# PIC16F1947 register map
Vendor: Microchip
Registers are 8-bit, read-write, reset 0x0 unless marked. A register's access mark holds for its fields unless they carry their own. Addresses are absolute, and some are shared; only a register's first bit layout is shown; [hi:lo] are bit positions; {n}, {i} and the like mark numbered series; 'fields as' and 'values as' point back to an identical list.

## SFR
0x00 INDF0 reset not defined — (power-on value xxxxxxxx)
0x01 INDF1 reset not defined — (power-on value xxxxxxxx)
0x02 PCL
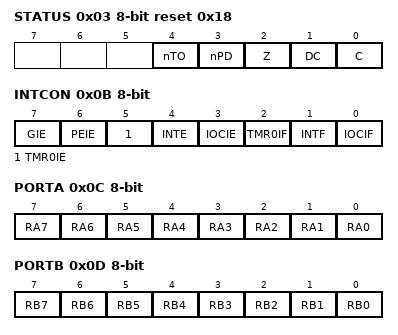
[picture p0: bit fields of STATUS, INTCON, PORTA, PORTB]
0x03 STATUS reset 0x18
  [4] nTO ro, [3] nPD ro, [2] Z, [1] DC, [0] C
0x04 FSR0L
0x05 FSR0H
0x06 FSR1L
0x07 FSR1H
0x08 BSR
  [4:0] BSR
0x09 WREG
  [7:0] WREG0
0x0A PCLATH
  [6:0] PCLATH
0x0B INTCON
  [7] GIE, [6] PEIE, [5] TMR0IE, [4] INTE, [3] IOCIE, [2] TMR0IF, [1] INTF, [0] IOCIF ro
0x0C PORTA reset not defined — (power-on value xxxxxxxx)
  [n] RA{n} (n=0..7)
0x0D PORTB reset not defined — (power-on value xxxxxxxx)
  [n] RB{n} (n=0..7)
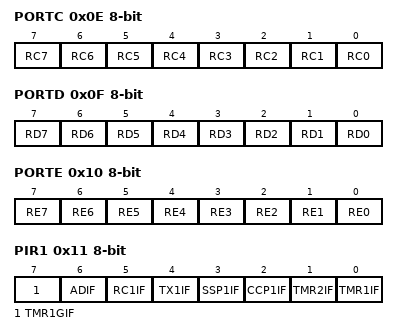
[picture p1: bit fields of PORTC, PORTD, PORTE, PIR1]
0x0E PORTC reset not defined — (power-on value xxxxxxxx)
  [n] RC{n} (n=0..7)
0x0F PORTD reset not defined — (power-on value xxxxxxxx)
  [n] RD{n} (n=0..7)
0x10 PORTE reset not defined — (power-on value xxxxxxxx)
  [n] RE{n} (n=0..7)
0x11 PIR1
  [7] TMR1GIF — Timer1 Gate Interrupt Flag bit
  [6] ADIF — A/D Converter Interrupt Flag bit
  [5] RC1IF ro — EUSART Receive Interrupt Flag bit
  [4] TX1IF ro — EUSART Transmit Interrupt Flag bit
  [3] SSP1IF — Master Synchronous Serial Port (MSSP) Interrupt Flag bit
  [2] CCP1IF — CCP1 Interrupt Flag bit
  [1] TMR2IF — TMR2 to PR2 Match Interrupt Flag bit
  [0] TMR1IF — TMR1 Overflow Interrupt Flag bit
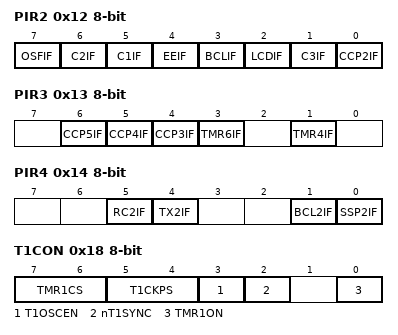
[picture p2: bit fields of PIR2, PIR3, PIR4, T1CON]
0x12 PIR2
  [7] OSFIF, [6] C2IF, [5] C1IF, [4] EEIF, [3] BCLIF, [2] LCDIF, [1] C3IF, [0] CCP2IF
0x13 PIR3
  [6] CCP5IF, [5] CCP4IF, [4] CCP3IF, [3] TMR6IF, [1] TMR4IF
0x14 PIR4
  [5] RC2IF ro, [4] TX2IF ro, [1] BCL2IF, [0] SSP2IF
0x15 TMR0 reset not defined — (power-on value xxxxxxxx)
0x16 TMR1L reset not defined — (power-on value xxxxxxxx)
0x17 TMR1H reset not defined — (power-on value xxxxxxxx)
0x18 T1CON
  [7:6] TMR1CS, [5:4] T1CKPS, [3] T1OSCEN, [2] nT1SYNC, [0] TMR1ON
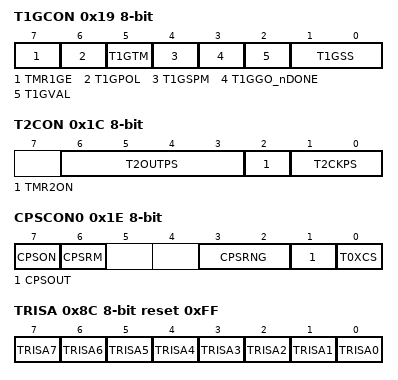
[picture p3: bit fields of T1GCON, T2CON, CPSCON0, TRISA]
0x19 T1GCON reset not defined — (power-on value 00000x00)
  [7] TMR1GE, [6] T1GPOL, [5] T1GTM, [4] T1GSPM, [3] T1GGO_nDONE, [2] T1GVAL ro, [1:0] T1GSS
0x1A TMR2
0x1B PR2 reset 0xFF
0x1C T2CON
  [6:3] T2OUTPS, [2] TMR2ON, [1:0] T2CKPS
0x1E CPSCON0
  [7] CPSON, [6] CPSRM, [3:2] CPSRNG, [1] CPSOUT ro, [0] T0XCS
0x1F CPSCON1
  [4:0] CPSCH
0x8C TRISA reset 0xFF — PORTA Data Direction Control Register
  [n] TRISA{n} (n=0..7)
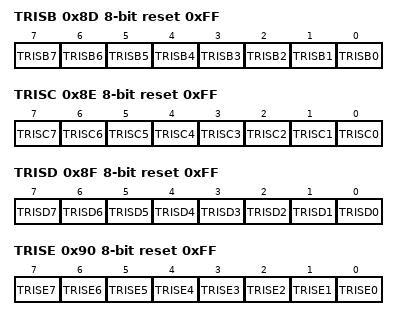
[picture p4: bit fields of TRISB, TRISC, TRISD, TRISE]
0x8D TRISB reset 0xFF — PORTB Data Direction Control Register
  [n] TRISB{n} (n=0..7)
0x8E TRISC reset 0xFF — PORTC Data Direction Control Register
  [n] TRISC{n} (n=0..7)
0x8F TRISD reset 0xFF — PORTD Data Direction Control Register
  [n] TRISD{n} (n=0..7)
0x90 TRISE reset 0xFF
  [n] TRISE{n} (n=0..7)
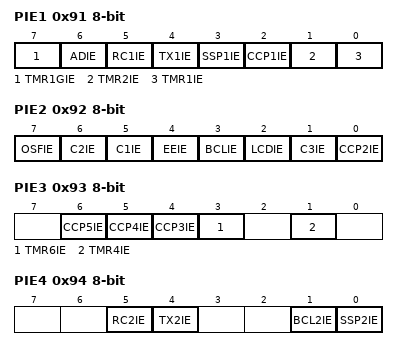
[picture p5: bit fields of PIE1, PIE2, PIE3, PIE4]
0x91 PIE1 — Peripheral Interrupt Enable Register 1
  [7] TMR1GIE — Timer1 Gate Interrupt Enable bit
  [6] ADIE — A/D Converter Interrupt Enable bit
  [5] RC1IE — EUSART Receive Interrupt Enable bit
  [4] TX1IE — EUSART Transmit Interrupt Enable bit
  [3] SSP1IE — Master Synchronous Serial Port (MSSP) Interrupt Enable bit
  [2] CCP1IE — CCP1 Interrupt Enable bit
  [1] TMR2IE — TMR2 to PR2 Match Interrupt Enable bit
  [0] TMR1IE — TMR1 Overflow Interrupt Enable bit
0x92 PIE2 — Peripheral Interrupt Enable Register 2
  [7] OSFIE — CCP2 Interrupt Enable bit
  [6] C2IE — Comparator C2 Interrupt Enable bit
  [5] C1IE — Comparator C1 Interrupt Enable bit
  [4] EEIE — EEPROM Write Completion Interrupt Enable bit
  [3] BCLIE — MSSP Bus Collision Interrupt Interrupt Enable bit
  [2] LCDIE — LCD Module Interrupt Enable bit
  [1] C3IE
  [0] CCP2IE — CCP2 Interrupt Enable bit
0x93 PIE3 — Peripheral Interrupt Enable Register 3
  [6] CCP5IE — CCP5 Interrupt Enable bit
  [5] CCP4IE — CCP4 Interrupt Enable bit
  [4] CCP3IE — CCP3 Interrupt Enable bit
  [3] TMR6IE — TMR6 to PR6 Match Interrupt Enable bit
  [1] TMR4IE — TMR4 to PR4 Match Interrupt Enable bit
0x94 PIE4
  [5] RC2IE, [4] TX2IE, [1] BCL2IE, [0] SSP2IE
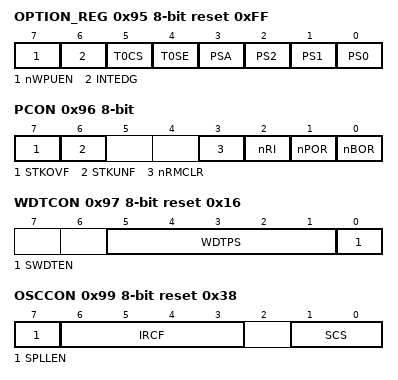
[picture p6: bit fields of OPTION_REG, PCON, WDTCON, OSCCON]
0x95 OPTION_REG reset 0xFF — Option Register
  [7] nWPUEN — Weak Pull-up Enable bit
  [6] INTEDG — Interrupt Edge Select bit
  [5] T0CS — TMR0 Clock Source Select bit
  [4] T0SE — TMR0 Source Edge Select bit
  [3] PSA — Prescaler Active bit
  [2] PS2 — Prescaler Rate Select bits
  [1] PS1 — Prescaler Rate Select bits
  [0] PS0 — Prescaler Rate Select bits
0x96 PCON reset not defined — Power Control Register (power-on value 00--11qq)
  [7] STKOVF — Stack Overflow Flag bit
  [6] STKUNF — Stack Underflow Flag bit
  [3] nRMCLR — MCLR Reset Flag bit
  [2] nRI — RESET Instruction Flag bit
  [1] nPOR — Power-on Reset Status bit
  [0] nBOR — Brown-out Reset Status bit
0x97 WDTCON reset 0x16 — Watchdog Timer Control Register
  [5:1] WDTPS — Watchdog Timer Period Select bits
  [0] SWDTEN — Software Enable/Disable for Watch Dog Timer bit
0x98 OSCTUNE — Oscillator Tuning Register
  [5:0] TUN — Frequency Tuning bits
0x99 OSCCON reset 0x38 — Oscillator Control Register
  [7] SPLLEN — Software PLL Enable bit
  [6:3] IRCF — Internal Oscillator Frequency Select bits
  [1:0] SCS — System clock select bit
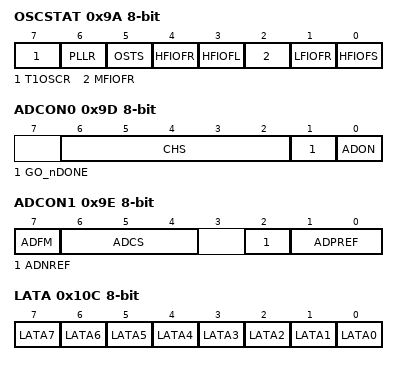
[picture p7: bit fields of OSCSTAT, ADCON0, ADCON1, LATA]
0x9A OSCSTAT ro reset not defined — Oscillator Status Register (power-on value 00q00q00)
  [7] T1OSCR — Timer1 Oscillator Ready bit
  [6] PLLR — 4x PLL Ready bit
  [5] OSTS — Oscillator Start-up Time-out Status bit
  [4] HFIOFR — High Freqency Internal Oscillator Ready bit
  [3] HFIOFL — High Freqency Internal Oscillator Status Locked bit
  [2] MFIOFR — Medium Freqency Internal Oscillator Ready bit
  [1] LFIOFR — Low Freqency Internal Oscillator Ready bit
  [0] HFIOFS — Low Freqency Internal Oscillator Ready bit
0x9B ADRESL reset not defined — A/D Result Register LSB (power-on value xxxxxxxx)
0x9C ADRESH reset not defined — A/D Result Register MSB (power-on value xxxxxxxx)
0x9D ADCON0 — Analog-to-Digital Control Register 0
  [6:2] CHS — Analog Channel Select bits
  [1] GO_nDONE — A/D Conversion Status bit
  [0] ADON — A/D Module Enable bit
0x9E ADCON1 — Analog-to-Digital Control Register 1
  [7] ADFM — A/D Result Format Select bit
  [6:4] ADCS — A/D Conversion Clock Select bits
  [2] ADNREF — A/D Negative Voltage Reference Configuration
  [1:0] ADPREF — A/D Positive Voltage Reference Configuration
0x10C LATA reset not defined — (power-on value xxxxxxxx)
  [n] LATA{n} (n=0..7)
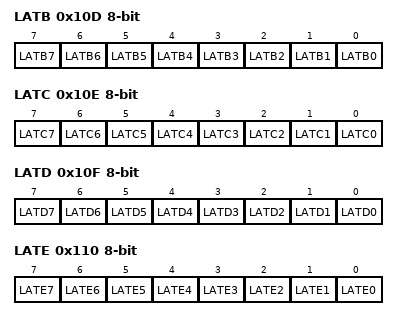
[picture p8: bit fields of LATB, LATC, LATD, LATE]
0x10D LATB reset not defined — (power-on value xxxxxxxx)
  [n] LATB{n} (n=0..7)
0x10E LATC reset not defined — (power-on value xxxxxxxx)
  [n] LATC{n} (n=0..7)
0x10F LATD reset not defined — (power-on value xxxxxxxx)
  [n] LATD{n} (n=0..7)
0x110 LATE reset not defined — (power-on value xxxxxxxx)
  [n] LATE{n} (n=0..7)
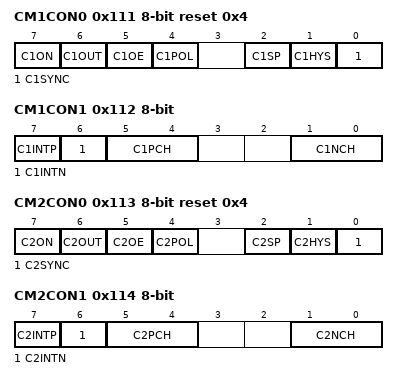
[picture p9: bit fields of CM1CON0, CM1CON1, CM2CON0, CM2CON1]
0x111 CM1CON0 reset 0x4
  [7] C1ON — Comparator Enable bit
  [6] C1OUT ro — Comparator Output bit
  [5] C1OE — Comparator Output Enable bit
  [4] C1POL — Comparator Output Polarity Select bit
  [2] C1SP — Comparator Speed/Power Select bit
  [1] C1HYS — Comparator Hysteresis Enable bit
  [0] C1SYNC — Comparator Output Synchronous Mode bit
0x112 CM1CON1
  [7] C1INTP — Comparator Interrupt on Positive going edge Enable bits
  [6] C1INTN — Comparator Interrupt on Negative going edge Enable bits
  [5:4] C1PCH — Comparator Positive Input Channel Select bits
  [1:0] C1NCH — Comparator Negative Input Channel Select bits
0x113 CM2CON0 reset 0x4
  [7] C2ON, [6] C2OUT ro, [5] C2OE, [4] C2POL, [2] C2SP, [1] C2HYS, [0] C2SYNC
0x114 CM2CON1
  [7] C2INTP — Comparator Interrupt on Positive going edge Enable bits
  [6] C2INTN — Comparator Interrupt on Negative going edge Enable bits
  [5:4] C2PCH — Comparator Positive Input Channel Select bits
  [1:0] C2NCH — Comparator Negative Input Channel Select bits
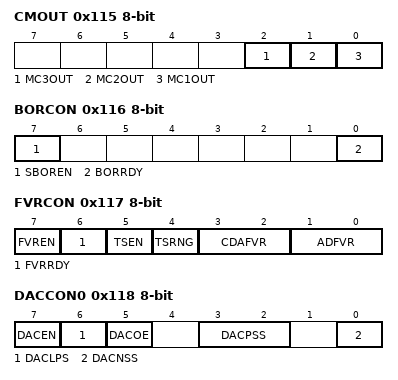
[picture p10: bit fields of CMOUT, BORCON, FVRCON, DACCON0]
0x115 CMOUT ro — Comparator Output Register
  [2] MC3OUT, [1] MC2OUT, [0] MC1OUT
0x116 BORCON reset not defined — Brown-out Reset Control Register (power-on value 1------q)
  [7] SBOREN — Software Brown Out Reset Enable bit
  [0] BORRDY ro — Brown-out Reset Circuit Ready Status bit
0x117 FVRCON reset not defined — Voltage Reference Control Register 0 (power-on value 0q000000)
  [7] FVREN — Fixed Voltage Reference Enable
  [6] FVRRDY ro — Fixed Voltage Reference Ready Flag
  [5] TSEN — Temperature Sensor Enable
  [4] TSRNG — Temperature Sensor Range Select
  [3:2] CDAFVR — Comparator and D/A Converter Fixed Voltage Reference Selection
  [1:0] ADFVR — A/D Converter Fixed Voltage Reference Selection
0x118 DACCON0 — Voltage Reference Control Register 1
  [7] DACEN — DAC 1 Enable bit
  [6] DACLPS — DAC 1 Low Power Voltage State Select bit
  [5] DACOE — DAC1 Voltage Output Enable bit
  [3:2] DACPSS — DAC1 Positive Source Select bits
  [0] DACNSS — DAC1 Negative Source Select bits
0x119 DACCON1 — Voltage Reference Control Register 2
  [4:0] DACR — DAC1 Voltage Output Select bits
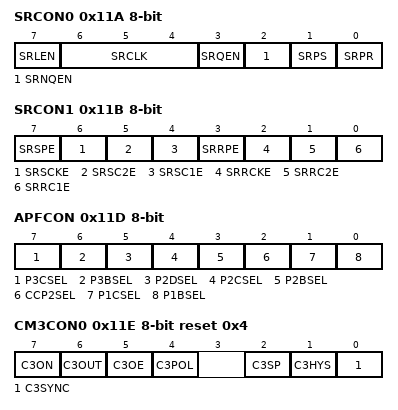
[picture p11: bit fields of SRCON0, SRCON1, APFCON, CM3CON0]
0x11A SRCON0 — SR Latch Control Register 0
  [7] SRLEN — SR Latch Enable bit
  [6:4] SRCLK — SR Latch Clock divider bits
  [3] SRQEN — SR Latch Q Output Enable bit
  [2] SRNQEN — SR Latch Q Output Enable bit
  [1] SRPS — Pulse Set Input of the SR Latch
  [0] SRPR — Pulse Reset Input of the SR Latch
0x11B SRCON1 — SR Latch Control Register 1
  [7] SRSPE — SR Latch Peripheral Set Enable bit
  [6] SRSCKE — SR Latch Set Clock Enable bit
  [5] SRSC2E — SR Latch C2 Set Enable bit
  [4] SRSC1E — SR Latch C1 Set Enable bit
  [3] SRRPE — SR Latch Peripheral Reset Enable bit
  [2] SRRCKE — SR Latch Reset Clock Enable bit
  [1] SRRC2E — SR Latch C2 Reset Enable bit
  [0] SRRC1E — SR Latch C1 Reset Enable bit
0x11D APFCON — Alternate Pin Function Control Register
  [7] P3CSEL — CCP3 PWM C Output pin selection bit
    0=P3C function is on RE3/P3C/COM0; 1=P3C function is on RD3/P3C/SEG3
  [6] P3BSEL — CCP3 PWM B output pin selection bit
  [5] P2DSEL — CCP2 PWM D output pin selection bit
  [4] P2CSEL — CCP2 PWM C Output Pin Selection
  [3] P2BSEL — CCP2 PWM B Output Pin Selection
  [2] CCP2SEL — CCP2 input/Output Pin Selection
  [1] P1CSEL — CCP1 PWM C output Pin Selection
  [0] P1BSEL — CCP1 PWM B output pin selection bit
0x11E CM3CON0 reset 0x4
  [7] C3ON — Comparator Enable bit
  [6] C3OUT ro — Comparator Output bit
  [5] C3OE — Comparator Output Enable bit
  [4] C3POL — Comparator Output Polarity Select bit
  [2] C3SP — Comparator Speed/Power Select bit
  [1] C3HYS — Comparator Hysteresis Enable bit
  [0] C3SYNC — Comparator Output Synchronous Mode bit
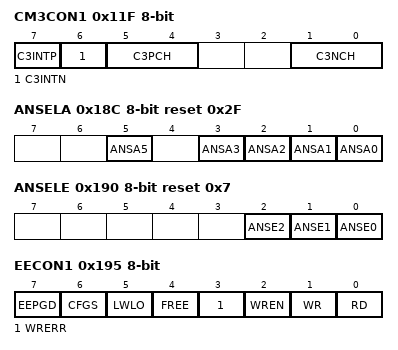
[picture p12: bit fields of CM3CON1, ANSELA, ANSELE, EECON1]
0x11F CM3CON1
  [7] C3INTP — Comparator Interrupt on Positive going edge Enable bits
  [6] C3INTN — Comparator Interrupt on Negative going edge Enable bits
  [5:4] C3PCH — Comparator Positive Input Channel Select bits
  [1:0] C3NCH — Comparator Negative Input Channel Select bits
0x18C ANSELA reset 0x2F
  [5] ANSA5, [n] ANSA{n} (n=0..3)
0x190 ANSELE reset 0x7
  [2] ANSE2, [1] ANSE1, [0] ANSE0
0x191 EEADRL
0x192 EEADRH reset 0x80
  [6:0] EEADRH
0x193 EEDATL reset not defined — (power-on value xxxxxxxx)
0x194 EEDATH reset not defined — (power-on value --xxxxxx)
  [5:0] EEDATH
0x195 EECON1 reset not defined — (power-on value 0000x000)
  [7] EEPGD — FLASH Program / Data EEPROM Memory Select bit
  [6] CFGS — FLASH Program / Data EEPROM or Configuration Select bit
  [5] LWLO — Load Write Latches Only bit
  [4] FREE — Program FLASH Erase Enable bit
  [3] WRERR — Sequence Error Flag bit
  [2] WREN — Program/Erase Enable bit
  [1] WR — Write Control bit (can only be set)
  [0] RD — Read Control bit (can only be set)
0x196 EECON2 wo reset not defined
0x199 RC1REG ro
  [7:0] RCREG
0x19A TX1REG
  [7:0] TXREG
0x19B SP1BRGL
  [7:0] SPBRGL
0x19C SP1BRGH
  [7:0] SPBRGH
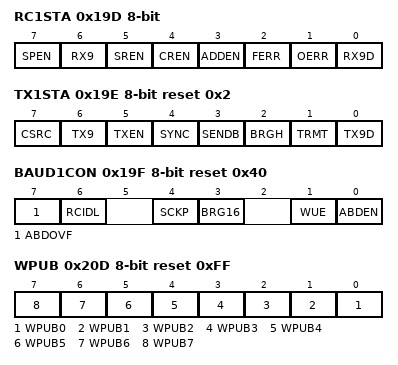
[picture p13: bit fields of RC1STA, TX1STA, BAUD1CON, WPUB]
0x19D RC1STA reset not defined — Receive Status and Control Register (power-on value 0000000x)
  [7] SPEN — Serial Port Enable bit
  [6] RX9 — 9-bit Receive Enable bit
  [5] SREN — Single Receive Enable bit
  [4] CREN — Continuous Receive Enable bit
  [3] ADDEN — Address Detect Enable bit
  [2] FERR ro — Framing Error bit
  [1] OERR ro — Overrun Error bit
  [0] RX9D ro — 9th bit of received data (can be parity bit)
0x19E TX1STA reset 0x2 — Transmit Status and Control Register
  [7] CSRC — Clock Source Select bit
  [6] TX9 — 9-bit Transmit Enable bit
  [5] TXEN — Transmit Enable bit
  [4] SYNC — USART Mode Select bit
  [3] SENDB — Send BREAK character bit
  [2] BRGH — High Baud Rate Select bit
  [1] TRMT ro — Transmit Operation Idle Status bit
  [0] TX9D — 9th bit of transmit data; can be used as parity bit
0x19F BAUD1CON reset 0x40 — Baud Rate Control Register
  [7] ABDOVF — BRG Rollover Status bit
  [6] RCIDL ro — Receive Operation Idle Status bit
  [4] SCKP — Clock/Transmit Polarity Select bit
  [3] BRG16 — 16-bit Baud Rate Register enable bit
  [1] WUE — Wake-Up Enable bit
  [0] ABDEN — Auto-Baud Detect Enable bit
0x20D WPUB reset 0xFF
  [n] WPUB{n} (n=0..7)
0x211 SSP1BUF reset not defined — (power-on value xxxxxxxx)
  [7:0] SSPBUF
0x212 SSP1ADD
  [7:0] SSPADD
0x213 SSP1MSK reset 0xFF
  [7:0] SSPMSK
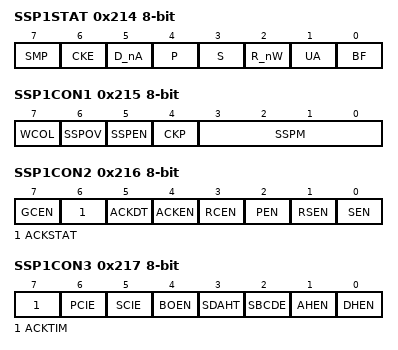
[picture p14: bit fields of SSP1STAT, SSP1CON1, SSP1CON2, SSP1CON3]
0x214 SSP1STAT
  [7] SMP, [6] CKE, [5] D_nA ro, [4] P ro, [3] S ro, [2] R_nW ro, [1] UA ro, [0] BF ro
0x215 SSP1CON1
  [7] WCOL, [6] SSPOV, [5] SSPEN, [4] CKP, [3:0] SSPM
0x216 SSP1CON2
  [7] GCEN, [6] ACKSTAT, [5] ACKDT, [4] ACKEN, [3] RCEN, [2] PEN, [1] RSEN, [0] SEN
0x217 SSP1CON3
  [7] ACKTIM ro, [6] PCIE, [5] SCIE, [4] BOEN, [3] SDAHT, [2] SBCDE, [1] AHEN, [0] DHEN
0x219 SSP2BUF reset not defined — (power-on value xxxxxxxx)
  [7:0] SSPBUF
0x21A SSP2ADD
  [7:0] SSPADD
0x21B SSP2MSK reset 0xFF
  [7:0] SSPMSK
0x21C SSP2STAT
  [7] SMP, [6] CKE, [5] D_nA, [4] P, [3] S, [2] R_nW, [1] UA, [0] BF
0x21D SSP2CON1
  [7] WCOL, [6] SSPOV, [5] SSPEN, [4] CKP, [3:0] SSPM
0x21E SSP2CON2
  fields as SSP1CON2
0x21F SSP2CON3
  fields as SSP1CON3
0x28C PORTF reset not defined — (power-on value xxxxxxxx)
  [n] RF{n} (n=0..7)
0x28D PORTG reset not defined — (power-on value --xxxxxx)
  [n] RG{n} (n=0..5)
0x291 CCPR1L reset not defined — (power-on value xxxxxxxx)
0x292 CCPR1H reset not defined — (power-on value xxxxxxxx)
0x293 CCP1CON
  [7:6] P1M, [5:4] DC1B, [3:0] CCP1M
0x294 PWM1CON
  [7] P1RSEN, [6:0] P1DC
0x295 CCP1AS
  [7] CCP1ASE, [6:4] CCP1AS, [3:2] PSS1AC, [1:0] PSS1BD
0x296 PSTR1CON reset 0x1
  [4] STR1SYNC, [3] STR1D, [2] STR1C, [1] STR1B, [0] STR1A
0x298 CCPR2L reset not defined — (power-on value xxxxxxxx)
0x299 CCPR2H reset not defined — (power-on value xxxxxxxx)
0x29A CCP2CON
  [7:6] P2M, [5:4] DC2B, [3:0] CCP2M
0x29B PWM2CON
  [7] P2RSEN, [6:0] P2DC
0x29C CCP2AS
  [7] CCP2ASE, [6:4] CCP2AS, [3:2] PSS2AC, [1:0] PSS2BD
0x29D PSTR2CON reset 0x1
  [4] STR2SYNC, [3] STR2D, [2] STR2C, [1] STR2B, [0] STR2A
0x29E CCPTMRS0
  [2n-1] C{n}TSEL1 (n=1..4), [2n-2] C{n}TSEL0 (n=1..4)
0x29F CCPTMRS1
  [1] C5TSEL1, [0] C5TSEL0
0x30C TRISF reset 0xFF
  [n] TRISF{n} (n=0..7)
0x30D TRISG reset 0x3F
  [5] TRISG5 ro, [n] TRISG{n} (n=0..4)
0x311 CCPR3L reset not defined — (power-on value xxxxxxxx)
0x312 CCPR3H reset not defined — (power-on value xxxxxxxx)
0x313 CCP3CON
  [7:6] P3M, [5:4] DC3B, [3:0] CCP3M
0x314 PWM3CON
  [7] P3RSEN, [6:0] P3DC
0x315 CCP3AS
  [7] CCP3ASE, [6:4] CCP3AS, [3:2] PSS3AC, [1:0] PSS3BD
0x316 PSTR3CON reset 0x1
  [4] STR3SYNC, [3] STR3D, [2] STR3C, [1] STR3B, [0] STR3A
0x318 CCPR4L reset not defined — (power-on value xxxxxxxx)
0x319 CCPR4H reset not defined — (power-on value xxxxxxxx)
0x31A CCP4CON
  [5:4] DC4B, [3:0] CCP4M
0x31C CCPR5L reset not defined — (power-on value xxxxxxxx)
0x31D CCPR5H reset not defined — (power-on value xxxxxxxx)
0x31E CCP5CON
  [5:4] DC5B, [3:0] CCP5M
0x38C LATF reset not defined — (power-on value xxxxxxxx)
  [n] LATF{n} (n=0..7)
0x38D LATG reset not defined — (power-on value ---xxxxx)
  [n] LATG{n} (n=0..5)
0x394 IOCBP — Interrupt-On-Change Positive Edge Register
  [n] IOCBP{n} (n=0..7)
0x395 IOCBN — Interrupt-On-Change Negative Edge Register
  [n] IOCBN{n} (n=0..7)
0x396 IOCBF — Interrupt-On-Change Flag Register
  [n] IOCBF{n} (n=0..7)
0x40C ANSELF reset 0xFF
  [n] ANSF{n} (n=0..7)
0x40D ANSELG reset 0x1E
  [n] ANSG{n} (n=1..4)
0x415 TMR4
0x416 PR4 reset 0xFF
0x417 T4CON — Timer2 Control Register
  [6:3] T4OUTPS — Timer2 Output Postscaler Select bits
  [2] TMR4ON — Timer2 On bit
  [1:0] T4CKPS — Timer2 Clock Prescale Select bits
0x41C TMR6
0x41D PR6 reset 0xFF
0x41E T6CON — Timer2 Control Register
  [6:3] T6OUTPS — Timer2 Output Postscaler Select bits
  [2] TMR6ON — Timer2 On bit
  [1:0] T6CKPS — Timer2 Clock Prescale Select bits
0x48D WPUG reset 0x20
  [5] WPUG5
0x491 RC2REG ro
  [7:0] RCREG
0x492 TX2REG
  [7:0] TXREG
0x493 SP2BRGL
  [7:0] SPBRGL
0x494 SP2BRGH
  [7:0] SPBRGH
0x495 RC2STA reset not defined — Receive Status and Control Register (power-on value 0000000x)
  fields as RC1STA
0x496 TX2STA reset 0x2 — Transmit Status and Control Register
  fields as TX1STA
0x497 BAUD2CON reset 0x40 — Baud Rate Control Register
  fields as BAUD1CON
0x791 LCDCON reset 0x3 — LCD Control Register
  [7] LCDEN — LCD Module Enable bit
  [6] SLPEN — LCD Display Sleep-Enabled bit
  [5] WERR — Write Failed Error bit (can only be cleared)
  [3:2] CS — Clock Source bits
  [1:0] LMUX — Commons Selection bits
0x792 LCDPS reset 0x3 — LCD Phase Register
  [7] WFT — Waveform Type bit
  [6] BIASMD — Bias Mode Selection bit
  [5] LCDA ro — LCD Active bit
  [4] WA ro — Write Allow bit
  [3:0] LP — LCD Prescaler Selection bits
0x793 LCDREF — LCD Reference Voltage Control Register
  [7] LCDIRE — LCD Internal Reference Enable bit
  [6] LCDIRS — LCD Internal Reference Source bit
  [5] LCDIRI — LCD Internal Reference Ladder Idle Enable bit
  [3] VLCD3PE — VLCD3 pin enable bit
  [2] VLCD2PE — VLCD2 pin enable bit
  [1] VLCD1PE — VLCD1 pin enable bit
0x794 LCDCST — LCD Contrast Control Register
  [2:0] LCDCST — LCD Contrast Control bits
0x795 LCDRL — LCD Reference Voltage Control Register
  [7:6] LRLAP — LCD Reference Ladder A Time Power Control bits
  [5:4] LRLBP — LCD Reference Ladder B Time Power Control bits
  [2:0] LRLAT — LCD Reference Ladder A Time interval control bits
0x798 LCDSE0
  [n] SE{n} (n=0..7)
0x799 LCDSE1
  [n-8] SE{n} (n=8..15)
0x79A LCDSE2
  [n-16] SE{n} (n=16..23)
0x79B LCDSE3
  [n-24] SE{n} (n=24..31)
0x79C LCDSE4
  [n-32] SE{n} (n=32..39)
0x79D LCDSE5
  [n-40] SE{n} (n=40..45)
0x7A0 LCDDATA0 reset not defined — (power-on value xxxxxxxx)
  [n] SEG{n}COM0 (n=0..7)
0x7A1 LCDDATA1 reset not defined — (power-on value xxxxxxxx)
  [n-8] SEG{n}COM0 (n=8..15)
0x7A2 LCDDATA2 reset not defined — (power-on value xxxxxxxx)
  [n-16] SEG{n}COM0 (n=16..23)
0x7A3 LCDDATA3 reset not defined — (power-on value xxxxxxxx)
  [n] SEG{n}COM1 (n=0..7)
0x7A4 LCDDATA4 reset not defined — (power-on value xxxxxxxx)
  [n-8] SEG{n}COM1 (n=8..15)
0x7A5 LCDDATA5 reset not defined — (power-on value xxxxxxxx)
  [n-16] SEG{n}COM1 (n=16..23)
0x7A6 LCDDATA6 reset not defined — (power-on value xxxxxxxx)
  [n] SEG{n}COM2 (n=0..7)
0x7A7 LCDDATA7 reset not defined — (power-on value xxxxxxxx)
  [n-8] SEG{n}COM2 (n=8..15)
0x7A8 LCDDATA8 reset not defined — (power-on value xxxxxxxx)
  [n-16] SEG{n}COM2 (n=16..23)
0x7A9 LCDDATA9 reset not defined — (power-on value xxxxxxxx)
  [n] SEG{n}COM3 (n=0..7)
0x7AA LCDDATA10 reset not defined — (power-on value xxxxxxxx)
  [n-8] SEG{n}COM3 (n=8..15)
0x7AB LCDDATA11 reset not defined — (power-on value xxxxxxxx)
  [n-16] SEG{n}COM3 (n=16..23)
0x7AC LCDDATA12 reset not defined — (power-on value xxxxxxxx)
  [n-24] SEG{n}COM0 (n=24..31)
0x7AD LCDDATA13 reset not defined — (power-on value xxxxxxxx)
  [n-32] SEG{n}COM0 (n=32..39)
0x7AE LCDDATA14 reset not defined — (power-on value --xxxxxx)
  [n-40] SEG{n}COM0 (n=40..45)
0x7AF LCDDATA15 reset not defined — (power-on value xxxxxxxx)
  [n-24] SEG{n}COM1 (n=24..31)
0x7B0 LCDDATA16 reset not defined — (power-on value xxxxxxxx)
  [n-32] SEG{n}COM1 (n=32..39)
0x7B1 LCDDATA17 reset not defined — (power-on value --xxxxxx)
  [n-40] SEG{n}COM1 (n=40..45)
0x7B2 LCDDATA18 reset not defined — (power-on value xxxxxxxx)
  [n-24] SEG{n}COM2 (n=24..31)
0x7B3 LCDDATA19 reset not defined — (power-on value xxxxxxxx)
  [n-32] SEG{n}COM2 (n=32..39)
0x7B4 LCDDATA20 reset not defined — (power-on value --xxxxxx)
  [n-40] SEG{n}COM2 (n=40..45)
0x7B5 LCDDATA21 reset not defined — (power-on value xxxxxxxx)
  [n-24] SEG{n}COM3 (n=24..31)
0x7B6 LCDDATA22 reset not defined — (power-on value xxxxxxxx)
  [n-32] SEG{n}COM3 (n=32..39)
0x7B7 LCDDATA23 reset not defined — (power-on value --xxxxxx)
  [n-40] SEG{n}COM3 (n=40..45)
0xFE4 STATUS_SHAD reset not defined — (power-on value -----xxx)
  [2] Z_SHAD, [1] DC_SHAD, [0] C_SHAD
0xFE5 WREG_SHAD reset not defined — (power-on value xxxxxxxx)
0xFE6 BSR_SHAD reset not defined — (power-on value ---xxxxx)
  [4:0] BSR_SHAD
0xFE7 PCLATH_SHAD reset not defined — (power-on value -xxxxxxx)
  [6:0] PCLATH_SHAD
0xFE8 FSR0L_SHAD reset not defined — (power-on value xxxxxxxx)
0xFE9 FSR0H_SHAD reset not defined — (power-on value xxxxxxxx)
0xFEA FSR1L_SHAD reset not defined — (power-on value xxxxxxxx)
0xFEB FSR1H_SHAD reset not defined — (power-on value xxxxxxxx)
0xFED STKPTR reset 0x1F — Current Stack pointer
  [4:0] STKPTR
0xFEE TOSL reset not defined — Top of Stack Low byte (power-on value xxxxxxxx)
0xFEF TOSH reset not defined — Top of Stack High byte (power-on value -xxxxxxx)
  [6:0] TOSH
